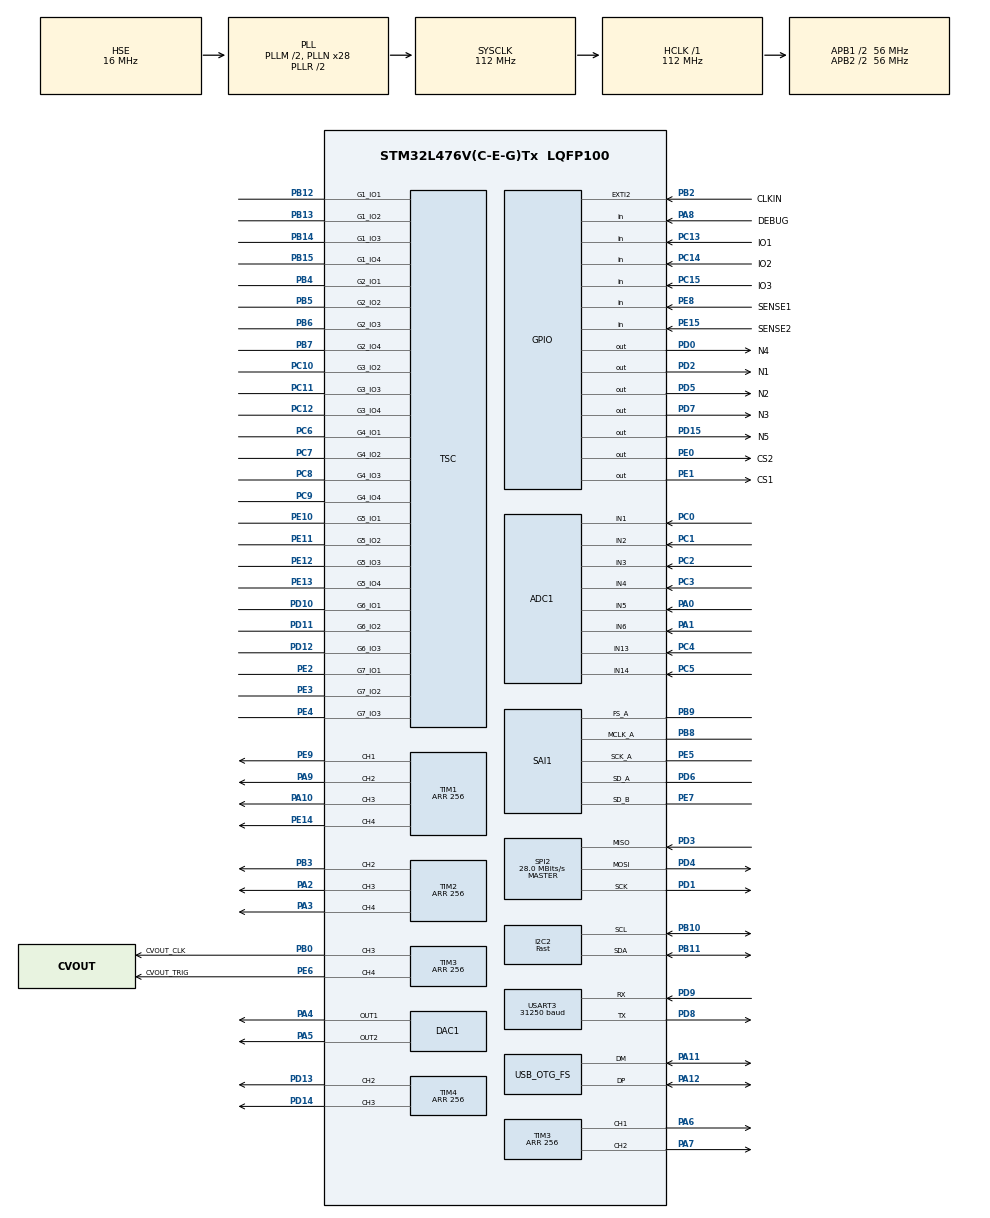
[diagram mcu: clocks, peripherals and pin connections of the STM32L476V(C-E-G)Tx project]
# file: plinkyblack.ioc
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Dma.USART3_RX.6.Instance=DMA1_Channel3
Dma.SPI2_TX.2.PeriphInc=DMA_PINC_DISABLE
Dma.SPI2_TX.2.MemInc=DMA_MINC_ENABLE
VP_TIM5_VS_ClockSourceINT.Mode=Internal
SH.S_TIM1_CH4.0=TIM1_CH4,PWM Generation4 CH4
TSC.ChannelIOs-G6_IO2=TSC_GROUP6_IO2
TSC.ChannelIOs-G6_IO3=TSC_GROUP6_IO3
Dma.SAI1_B.4.Priority=DMA_PRIORITY_LOW
SPI2.VirtualType=VM_MASTER
PB10.Mode=I2C
Dma.SAI1_B.4.MemInc=DMA_MINC_ENABLE
ADC1.SamplingTime-6\#ChannelRegularConversion=ADC_SAMPLETIME_24CYCLES_5
PC12.Signal=TSC_G3_IO4
PE8.GPIO_PuPd=GPIO_PULLUP
PE1.PinState=GPIO_PIN_SET
SAI1.Instance-SAI_A_MasterWithClock=SAI$Index_Block_A
PA15\ (JTDI).Signal=SYS_JTDI
RCC.DATA_CACHE_ENABLE=0
PB13.Signal=TSC_G1_IO2
TIM3.Channel-PWM\ Generation4\ CH4=TIM_CHANNEL_4
PE6.GPIO_Label=CVOUT_TRIG
RCC.SYSCLKSource=RCC_SYSCLKSOURCE_PLLCLK
NVIC.DMA1_Channel3_IRQn=true\:0\:0\:false\:false\:true\:false\:true
USART3.VirtualMode-Asynchronous=VM_ASYNC
PA14\ (JTCK-SWCLK).Signal=SYS_JTCK-SWCLK
USART3.BaudRate=31250
ADC1.Channel-5\#ChannelRegularConversion=ADC_CHANNEL_6
RCC.ADCCLockSelection=RCC_ADCCLKSOURCE_PLLSAI2
Dma.USART3_TX.5.PeriphDataAlignment=DMA_PDATAALIGN_BYTE
PE2.Mode=G7_IO1-Sampling
PD4.Signal=SPI2_MOSI
I2C2.I2C_Speed_Mode=I2C_Fast
RCC.APB2TimFreq_Value=112000000
PB6.Signal=TSC_G2_IO3
ADC1.Channel-2\#ChannelRegularConversion=ADC_CHANNEL_3
PC7.Signal=TSC_G4_IO2
Dma.ADC1.1.PeriphDataAlignment=DMA_PDATAALIGN_HALFWORD
TSC.SpreadSpectrum=DISABLE
PB6.Mode=G2_IO3-Channel
PC3.Signal=ADCx_IN4
PD0.Signal=GPIO_Output
PD8.Signal=USART3_TX
PE5.Signal=SAI1_SCK_A
PE1.Signal=GPIO_Output
RCC.PREFETCH_ENABLE=1
TIM4.Channel-PWM\ Generation3\ CH3=TIM_CHANNEL_3
TIM1.OCFastMode_PWM-PWM\ Generation4\ CH4=TIM_OCFAST_ENABLE
PB2.Signal=GPXTI2
Dma.USART3_RX.6.Direction=DMA_PERIPH_TO_MEMORY
Dma.SAI1_B.4.Instance=DMA2_Channel2
RCC.SAI1CLockSelection=RCC_SAI1CLKSOURCE_PLLSAI2
TIM1.Channel-PWM\ Generation1\ CH1=TIM_CHANNEL_1
PE9.Signal=S_TIM1_CH1
PB14.Mode=G1_IO3-Channel
PC9.Mode=G4_IO4-Channel
SPI2.CalculateBaudRate=28.0 MBits/s
TSC.ChannelIOs-G5_IO4=TSC_GROUP5_IO4
SH.S_TIM4_CH2.0=TIM4_CH2,PWM Generation2 CH2
TSC.ChannelIOs-G5_IO3=TSC_GROUP5_IO3
TSC.ChannelIOs-G5_IO2=TSC_GROUP5_IO2
PE2.Signal=TSC_G7_IO1
PA8.Signal=GPIO_Input
PE13.Mode=G5_IO4-Channel
TIM4.Period=256
PD3.Mode=Full_Duplex_Master
PE10.Signal=TSC_G5_IO1
PB2.GPIO_PuPd=GPIO_PULLUP
VP_TIM1_VS_ClockSourceINT.Mode=Internal
ADC1.SamplingTime-0\#ChannelRegularConversion=ADC_SAMPLETIME_24CYCLES_5
PA0.Signal=ADCx_IN5
ADC1.OffsetNumber-5\#ChannelRegularConversion=ADC_OFFSET_NONE
Mcu.Package=LQFP100
PB9.Signal=SAI1_FS_A
SAI1.AudioFrequency-SAI_A_MasterWithClock=SAI_AUDIO_FREQUENCY_32K
SPI2.Mode=SPI_MODE_MASTER
ADC1.OversamplingMode=ENABLE
SH.ADCx_IN14.0=ADC1_IN14,IN14-Single-Ended
PD12.Signal=TSC_G6_IO3
TIM1.OCFastMode_PWM-PWM\ Generation3\ CH3=TIM_OCFAST_ENABLE
Dma.SPI2_TX.2.Mode=DMA_NORMAL
PA10.Signal=S_TIM1_CH3
PC11.Mode=G3_IO3-Channel
TIM2.OCFastMode_PWM-PWM\ Generation4\ CH4=TIM_OCFAST_ENABLE
RCC.APB2CLKDivider=RCC_HCLK_DIV2
NVIC.EXTI2_IRQn=true\:0\:0\:false\:false\:true\:true\:true
PD4.Mode=Full_Duplex_Master
RCC.APB1TimFreq_Value=112000000
TIM1.Period=256
PB13.Mode=G1_IO2-Channel
NVIC.DMA1_Channel4_IRQn=true\:0\:0\:false\:false\:true\:false\:true
PA13\ (JTMS-SWDIO).Signal=SYS_JTMS-SWDIO
TSC.MaxCountValue=TSC_MCV_16383
PD9.GPIO_PuPd=GPIO_PULLUP
PH0-OSC_IN\ (PH0).Mode=HSE-External-Oscillator
ADC1.EOCSelection=ADC_EOC_SEQ_CONV
PD15.Signal=GPIO_Output
TSC.SamplingIOs-G1_IO1=TSC_GROUP1_IO1
ADC1.Rank-4\#ChannelRegularConversion=5
PE12.Mode=G5_IO3-Channel
USART3.RxPinLevelInvertParam=ADVFEATURE_RXINV_DISABLE
Dma.SAI1_B.4.PeriphInc=DMA_PINC_DISABLE
PC15-OSC32_OUT\ (PC15).GPIO_Label=IO3
ADC1.Rank-0\#ChannelRegularConversion=1
DAC1.DAC_Channel-DAC_OUT2=DAC_CHANNEL_2
VP_SAI1_VP_$IpInstance_SAIA_SAI_BASIC.Mode=SAI_A_BASIC
Dma.USART3_RX.6.MemDataAlignment=DMA_MDATAALIGN_BYTE
SH.ADCx_IN6.0=ADC1_IN6,IN6-Single-Ended
SAI1.MClockEnable-SAI_A_MasterWithClock=SAI_MASTERCLOCK_ENABLE
ADC1.OffsetNumber-0\#ChannelRegularConversion=ADC_OFFSET_NONE
PC13.Signal=GPIO_Input
PD3.Signal=SPI2_MISO
PC6.Signal=TSC_G4_IO1
PE10.Mode=G5_IO1-Sampling
PC2.Signal=ADCx_IN3
PD7.Signal=GPIO_Output
PD1.Signal=SPI2_SCK
Dma.USART3_TX.5.Instance=DMA1_Channel2
SAI1.ErrorAudioFreq-SAI_A_MasterWithClock=-2.34 %
Dma.SAI1_B.4.MemDataAlignment=DMA_MDATAALIGN_HALFWORD
PC0.Signal=ADCx_IN1
RCC.APB1CLKDivider=RCC_HCLK_DIV2
Dma.USART3_RX.6.PeriphInc=DMA_PINC_DISABLE
TSC.SamplingIOs-G6_IO1=TSC_GROUP6_IO1
PD6.Mode=SAI_A_MasterWithClock
PD0.GPIO_Speed=GPIO_SPEED_FREQ_LOW
ADC1.Channel-7\#ChannelRegularConversion=ADC_CHANNEL_14
PC14-OSC32_IN\ (PC14).GPIO_Label=IO2
PE0.GPIO_Speed=GPIO_SPEED_FREQ_VERY_HIGH
PD10.Signal=TSC_G6_IO1
TIM1.AutoReloadPreload=TIM_AUTORELOAD_PRELOAD_DISABLE
TIM3.Channel-PWM\ Generation3\ CH3=TIM_CHANNEL_3
PA8.GPIO_Label=DEBUG
PB11.Mode=I2C
SH.COMP_DAC11_group.0=DAC1_OUT1,DAC_OUT1
PC6.Mode=G4_IO1-Sampling
PE8.GPIO_Label=SENSE1
PA9.Signal=S_TIM1_CH2
TIM1.Channel-PWM\ Generation2\ CH2=TIM_CHANNEL_2
Dma.USART3_TX.5.PeriphInc=DMA_PINC_DISABLE
Dma.USART3_TX.5.Mode=DMA_NORMAL
PD8.Mode=Asynchronous
TSC.ChannelIOs-G7_IO3=TSC_GROUP7_IO3
TSC.ChannelIOs-G7_IO2=TSC_GROUP7_IO2
PB10.Signal=I2C2_SCL
SAI1.VirtualMode-SAI_A_MasterWithClock=VM_MASTER
TSC.CTPulseHighLength=TSC_CTPH_7CYCLES
VP_SAI1_VP_$IpInstance_SAIB_SAI_BASIC.Mode=SAI_B_BASIC
PB14.Signal=TSC_G1_IO3
PA5.Signal=COMP_DAC12_group
PC12.Mode=G3_IO4-Channel
PE1.GPIO_Label=CS1
PD1.Mode=Full_Duplex_Master
Dma.SAI1_A.0.PeriphInc=DMA_PINC_DISABLE
TSC.SamplingIOs-G7_IO1=TSC_GROUP7_IO1
PE14.Signal=S_TIM1_CH4
PE15.Signal=GPIO_Input
PE8.Signal=GPIO_Input
SH.ADCx_IN4.0=ADC1_IN4,IN4-Single-Ended
SAI1.FIFOThreshold-SAI_A_MasterWithClock=SAI_FIFOTHRESHOLD_HF
ADC1.DMAContinuousRequests=ENABLE
Dma.USART3_RX.6.Mode=DMA_CIRCULAR
TIM2.Period=256
PB4\ (NJTRST).Mode=G2_IO1-Sampling
Dma.SAI1_B.4.PeriphDataAlignment=DMA_PDATAALIGN_HALFWORD
ADC1.ExternalTrigConv=ADC_EXTERNALTRIG_T6_TRGO
PC8.Mode=G4_IO3-Channel
PA13\ (JTMS-SWDIO).Mode=Serial_Wire
PA4.Signal=COMP_DAC11_group
ADC1.SamplingTime-1\#ChannelRegularConversion=ADC_SAMPLETIME_24CYCLES_5
PB5.Signal=TSC_G2_IO2
ADC1.master=1
PD12.Mode=G6_IO3-Channel
PD11.Signal=TSC_G6_IO2
ADC1.Rank-1\#ChannelRegularConversion=2
PA11.Signal=USB_OTG_FS_DM
NVIC.DMA2_Channel1_IRQn=true\:1\:0\:true\:false\:true\:false\:true
ProjectManager.HeapSize=0x200
ADC1.SamplingTime-5\#ChannelRegularConversion=ADC_SAMPLETIME_24CYCLES_5
SH.ADCx_IN5.0=ADC1_IN5,IN5-Single-Ended
VP_TIM4_VS_ClockSourceINT.Mode=Internal
SAI1.VirtualProtocol-SAI_B_BASIC=VM_BASIC_PROTOCOL
NVIC.PriorityGroup=NVIC_PRIORITYGROUP_4
TIM3.Channel-PWM\ Generation2\ CH2=TIM_CHANNEL_2
PB8.Mode=SAI_A_MasterWithClock
TSC.CTPulseLowLength=TSC_CTPL_7CYCLES
PE3.Signal=TSC_G7_IO2
TIM2.AutoReloadPreload=TIM_AUTORELOAD_PRELOAD_DISABLE
SPI2.DataSize=SPI_DATASIZE_8BIT
NVIC.DMA1_Channel1_IRQn=true\:0\:0\:false\:false\:true\:false\:true
TIM1.Channel-PWM\ Generation3\ CH3=TIM_CHANNEL_3
PD2.Signal=GPIO_Output
PB0.Signal=S_TIM3_CH3
ADC1.Rank-5\#ChannelRegularConversion=6
RCC.USART3CLockSelection=RCC_USART3CLKSOURCE_HSI
PC1.Signal=ADCx_IN2
Dma.SAI1_A.0.Instance=DMA2_Channel1
Dma.USART3_RX.6.PeriphDataAlignment=DMA_PDATAALIGN_BYTE
PD2.GPIO_Label=N1
Dma.SAI1_A.0.PeriphDataAlignment=DMA_PDATAALIGN_HALFWORD
Mcu.Family=STM32L4
NVIC.USART3_IRQn=true\:0\:0\:false\:false\:true\:true\:true
Dma.USART3_TX.5.MemInc=DMA_MINC_ENABLE
RCC.CortexFreq_Value=112000000
Dma.ADC1.1.MemDataAlignment=DMA_MDATAALIGN_HALFWORD
NVIC.DMA1_Channel5_IRQn=true\:0\:0\:false\:false\:true\:false\:true
PC14-OSC32_IN\ (PC14).GPIO_PuPd=GPIO_PULLUP
ADC1.OffsetNumber-7\#ChannelRegularConversion=ADC_OFFSET_NONE
ADC1.ContinuousConvMode=DISABLE
PH0-OSC_IN\ (PH0).Signal=RCC_OSC_IN
SH.COMP_DAC12_group.0=DAC1_OUT2,DAC_OUT2
SH.ADCx_IN2.0=ADC1_IN2,IN2-Single-Ended
PC10.Signal=TSC_G3_IO2
ADC1.OffsetNumber-4\#ChannelRegularConversion=ADC_OFFSET_NONE
I2C2.Timing=0x00501D63
SAI1.VirtualProtocol-SAI_A_BASIC=VM_BASIC_PROTOCOL
PD0.GPIO_Label=N4
PA11.Mode=Device_Only
PB0.GPIO_Label=CVOUT_CLK
TSC.ChannelIOs-G2_IO2=TSC_GROUP2_IO2
TIM1.OCFastMode_PWM-PWM\ Generation1\ CH1=TIM_OCFAST_ENABLE
TSC.ChannelIOs-G2_IO3=TSC_GROUP2_IO3
TIM2.Channel-PWM\ Generation2\ CH2=TIM_CHANNEL_2
TSC.ChannelIOs-G2_IO4=TSC_GROUP2_IO4
PC13.GPIO_Label=IO1
PB11.Signal=I2C2_SDA
PB15.Signal=TSC_G1_IO4
PD9.Mode=Asynchronous
ProjectManager.StackSize=0x400
PB3\ (JTDO-TRACESWO).Signal=S_TIM2_CH2
PD13.Signal=S_TIM4_CH2
PB2.GPIO_ModeDefaultEXTI=GPIO_MODE_IT_FALLING
PA12.Signal=USB_OTG_FS_DP
Dma.SAI1_B.4.Mode=DMA_CIRCULAR
SPI2.CLKPolarity=SPI_POLARITY_HIGH
PE11.Mode=G5_IO2-Channel
SAI1.VirtualMode-SAI_B_SyncSlave=VM_SLAVE
TSC.SamplingIOs-G4_IO1=TSC_GROUP4_IO1
Dma.ADC1.1.Instance=DMA1_Channel1
TIM1.Channel-PWM\ Generation4\ CH4=TIM_CHANNEL_4
ADC1.Channel-3\#ChannelRegularConversion=ADC_CHANNEL_4
RCC.HCLKFreq_Value=112000000
SH.ADCx_IN3.0=ADC1_IN3,IN3-Single-Ended
TIM3.Period=256
Dma.SPI2_TX.2.PeriphDataAlignment=DMA_PDATAALIGN_BYTE
PD10.Mode=G6_IO1-Sampling
Dma.SPI2_TX.2.Instance=DMA1_Channel5
Dma.SPI2_RX.3.Priority=DMA_PRIORITY_HIGH
RCC.AHBFreq_Value=112000000
SPI2.BaudRatePrescaler=SPI_BAUDRATEPRESCALER_2
TIM3.Channel-PWM\ Generation1\ CH1=TIM_CHANNEL_1
Dma.USART3_TX.5.Direction=DMA_MEMORY_TO_PERIPH
ADC1.Channel-0\#ChannelRegularConversion=ADC_CHANNEL_1
PH1-OSC_OUT\ (PH1).Mode=HSE-External-Oscillator
NVIC.DMA2_Channel2_IRQn=true\:1\:0\:true\:false\:true\:false\:true
RCC.HSE_VALUE=16000000
ADC1.SamplingTime-4\#ChannelRegularConversion=ADC_SAMPLETIME_24CYCLES_5
ADC1.Channel-6\#ChannelRegularConversion=ADC_CHANNEL_13
ADC1.Rank-2\#ChannelRegularConversion=3
PE13.Signal=TSC_G5_IO4
PD0.PinState=GPIO_PIN_RESET
Dma.SPI2_RX.3.PeriphDataAlignment=DMA_PDATAALIGN_BYTE
PB5.Mode=G2_IO2-Channel
Dma.ADC1.1.Priority=DMA_PRIORITY_LOW
PC13.GPIO_PuPd=GPIO_PULLUP
SAI1.InitProtocol-SAI_A_MasterWithClock=Enable
RCC.PLLSAI2N=14
PB7.Signal=TSC_G2_IO4
Dma.ADC1.1.Mode=DMA_CIRCULAR
TSC.PulseGeneratorPrescaler=TSC_PG_PRESC_DIV2
TSC.SamplingIOs-G5_IO1=TSC_GROUP5_IO1
PE4.Mode=G7_IO3-Channel
SH.S_TIM3_CH1.0=TIM3_CH1,PWM Generation1 CH1
TIM6.Period=12000
TIM4.OCFastMode_PWM-PWM\ Generation2\ CH2=TIM_OCFAST_ENABLE
Dma.SPI2_TX.2.MemDataAlignment=DMA_MDATAALIGN_BYTE
PE4.Signal=TSC_G7_IO3
TSC.SpreadSpectrumPrescaler=TSC_SS_PRESC_DIV1
PD7.GPIO_Label=N3
SAI1.OutputDrive-SAI_A_MasterWithClock=SAI_OUTPUTDRIVE_ENABLE
PA6.Signal=S_TIM3_CH1
PB12.Mode=G1_IO1-Sampling
TSC.ChannelIOs-G1_IO4=TSC_GROUP1_IO4
Dma.SPI2_TX.2.Priority=DMA_PRIORITY_HIGH
TSC.ChannelIOs-G1_IO2=TSC_GROUP1_IO2
TSC.ChannelIOs-G1_IO3=TSC_GROUP1_IO3
Dma.USART3_TX.5.Priority=DMA_PRIORITY_LOW
Dma.SAI1_A.0.MemDataAlignment=DMA_MDATAALIGN_HALFWORD
Dma.ADC1.1.Direction=DMA_PERIPH_TO_MEMORY
RCC.EnbaleCSS=true
PD5.GPIO_Label=N2
Dma.ADC1.1.MemInc=DMA_MINC_ENABLE
USB_OTG_FS.VirtualMode=Device_Only
ADC1.OffsetNumber-1\#ChannelRegularConversion=ADC_OFFSET_NONE
SPI2.CLKPhase=SPI_PHASE_2EDGE
PE0.GPIO_Label=CS2
Dma.SPI2_RX.3.Mode=DMA_NORMAL
SH.ADCx_IN1.0=ADC1_IN1,IN1-Single-Ended
Dma.Request2=SPI2_TX
Dma.Request1=ADC1
Dma.Request4=SAI1_B
Dma.Request3=SPI2_RX
USART3.OverrunDisableParam=ADVFEATURE_OVERRUN_DISABLE
Dma.Request6=USART3_RX
Dma.SPI2_RX.3.PeriphInc=DMA_PINC_DISABLE
Dma.Request5=USART3_TX
SPI2.Direction=SPI_DIRECTION_2LINES
PC5.Signal=ADCx_IN14
PE7.Signal=SAI1_SD_B
PD6.Signal=SAI1_SD_A
ADC1.Rank-6\#ChannelRegularConversion=7
Dma.Request0=SAI1_A
PE3.Mode=G7_IO2-Channel
Dma.SAI1_B.4.Direction=DMA_PERIPH_TO_MEMORY
VP_TIM3_VS_ClockSourceINT.Mode=Internal
RCC.PLLSAI1N=12
PA3.Signal=S_TIM2_CH4
RCC.MSI_VALUE=4000000
RCC.PLLSourceVirtual=RCC_PLLSOURCE_HSE
PA14\ (JTCK-SWCLK).Mode=Serial_Wire
TIM2.Channel-PWM\ Generation4\ CH4=TIM_CHANNEL_4
SH.ADCx_IN13.0=ADC1_IN13,IN13-Single-Ended
TIM4.AutoReloadPreload=TIM_AUTORELOAD_PRELOAD_DISABLE
PD15.GPIO_Label=N5
ADC1.Channel-4\#ChannelRegularConversion=ADC_CHANNEL_5
Dma.SAI1_A.0.Direction=DMA_MEMORY_TO_PERIPH
PC11.Signal=TSC_G3_IO3
ADC1.OffsetNumber-3\#ChannelRegularConversion=ADC_OFFSET_NONE
PC8.Signal=TSC_G4_IO3
PC4.Signal=ADCx_IN13
PC10.Mode=G3_IO2-Sampling
VP_TIM6_VS_ClockSourceINT.Mode=Enable_Timer
TSC.ChannelIOs-G4_IO4=TSC_GROUP4_IO4
Dma.SPI2_RX.3.MemDataAlignment=DMA_MDATAALIGN_BYTE
TSC.ChannelIOs-G4_IO3=TSC_GROUP4_IO3
PC15-OSC32_OUT\ (PC15).Signal=GPIO_Input
PD9.Signal=USART3_RX
PD5.Signal=GPIO_Output
TSC.ChannelIOs-G4_IO2=TSC_GROUP4_IO2
Dma.SAI1_A.0.MemInc=DMA_MINC_ENABLE
TIM4.OCFastMode_PWM-PWM\ Generation3\ CH3=TIM_OCFAST_ENABLE
SH.S_TIM3_CH3.0=TIM3_CH3,PWM Generation3 CH3
ADC1.SamplingTime-2\#ChannelRegularConversion=ADC_SAMPLETIME_24CYCLES_5
PH1-OSC_OUT\ (PH1).Signal=RCC_OSC_OUT
TIM1.OCFastMode_PWM-PWM\ Generation2\ CH2=TIM_OCFAST_ENABLE
Dma.USART3_RX.6.MemInc=DMA_MINC_ENABLE
Dma.SPI2_RX.3.MemInc=DMA_MINC_ENABLE
TSC.SamplingIOs-G2_IO1=TSC_GROUP2_IO1
SAI1.RealAudioFreq-SAI_A_MasterWithClock=31.25 KHz
SH.S_TIM2_CH2.0=TIM2_CH2,PWM Generation2 CH2
PE0.PinState=GPIO_PIN_SET
SH.S_TIM1_CH1.0=TIM1_CH1,PWM Generation1 CH1
PE15.GPIO_Label=SENSE2
NVIC.DMA1_Channel2_IRQn=true\:0\:0\:false\:false\:true\:false\:true
ProjectManager.TargetToolchain=STM32CubeIDE
Dma.SAI1_A.0.Mode=DMA_CIRCULAR
Dma.SPI2_TX.2.Direction=DMA_MEMORY_TO_PERIPH
SH.S_TIM4_CH3.0=TIM4_CH3,PWM Generation3 CH3
PB9.Mode=SAI_A_MasterWithClock
ADC1.Channel-1\#ChannelRegularConversion=ADC_CHANNEL_2
TSC.SpreadSpectrumDeviation=32
RCC.USBFreq_Value=48000000
TIM2.OCFastMode_PWM-PWM\ Generation3\ CH3=TIM_OCFAST_ENABLE
ADC1.Ratio=ADC_OVERSAMPLING_RATIO_16
PE11.Signal=TSC_G5_IO2
RCC.LSE_VALUE=32768
PA1.Signal=ADCx_IN6
Dma.SAI1_A.0.Priority=DMA_PRIORITY_LOW
SH.S_TIM3_CH2.0=TIM3_CH2,PWM Generation2 CH2
board=custom
RCC.VCOOutputFreq_Value=224000000
Dma.SPI2_RX.3.Instance=DMA1_Channel4
PB15.Mode=G1_IO4-Channel
PC15-OSC32_OUT\ (PC15).GPIO_PuPd=GPIO_PULLUP
TIM4.Channel-PWM\ Generation2\ CH2=TIM_CHANNEL_2
RCC.APB2Freq_Value=56000000
SH.S_TIM1_CH2.0=TIM1_CH2,PWM Generation2 CH2
VP_TIM2_VS_ClockSourceINT.Mode=Internal
SH.S_TIM2_CH3.0=TIM2_CH3,PWM Generation3 CH3
PE1.GPIO_Speed=GPIO_SPEED_FREQ_VERY_HIGH
RCC.INSTRUCTION_CACHE_ENABLE=1
PE5.Mode=SAI_A_MasterWithClock
RCC.ADCFreq_Value=56000000
TIM2.Channel-PWM\ Generation3\ CH3=TIM_CHANNEL_3
TIM6.TIM_MasterOutputTrigger=TIM_TRGO_UPDATE
Dma.USART3_RX.6.Priority=DMA_PRIORITY_LOW
Dma.ADC1.1.PeriphInc=DMA_PINC_DISABLE
DAC1.DAC_Trigger-DAC_OUT2=DAC_TRIGGER_NONE
DAC1.DAC_Trigger-DAC_OUT1=DAC_TRIGGER_NONE
PE6.Signal=S_TIM3_CH4
ADC1.NbrOfConversion=8
ADC1.OffsetNumber-2\#ChannelRegularConversion=ADC_OFFSET_NONE
Mcu.Name=STM32L476V(C-E-G)Tx
PE0.Signal=GPIO_Output
PE12.Signal=TSC_G5_IO3
PA2.Signal=S_TIM2_CH3
ADC1.OffsetNumber-6\#ChannelRegularConversion=ADC_OFFSET_NONE
PD14.Signal=S_TIM4_CH3
RCC.SYSCLKFreq_VALUE=112000000
TSC.ChannelIOs-G3_IO4=TSC_GROUP3_IO4
PE7.Mode=SAI_B_SyncSlave
TSC.ChannelIOs-G3_IO3=TSC_GROUP3_IO3
PA12.Mode=Device_Only
ADC1.Rank-3\#ChannelRegularConversion=4
ADC1.SamplingTime-3\#ChannelRegularConversion=ADC_SAMPLETIME_24CYCLES_5
TIM5.Prescaler=80
TSC.SamplingIOs-G3_IO2=TSC_GROUP3_IO2
PC14-OSC32_IN\ (PC14).Signal=GPIO_Input
SAI1.Instance-SAI_B_SyncSlave=SAI$Index_Block_B
PB7.Mode=G2_IO4-Channel
PB2.GPIO_Label=CLKIN
PE15.GPIO_PuPd=GPIO_PULLUP
SH.S_TIM2_CH4.0=TIM2_CH4,PWM Generation4 CH4
Dma.USART3_TX.5.MemDataAlignment=DMA_MDATAALIGN_BYTE
PD11.Mode=G6_IO2-Channel
SH.S_TIM1_CH3.0=TIM1_CH3,PWM Generation3 CH3
NVIC.I2C2_EV_IRQn=true\:0\:0\:false\:false\:true\:true\:true
RCC.HSI_VALUE=16000000
PA8.GPIO_PuPd=GPIO_PULLUP
ADC1.Rank-7\#ChannelRegularConversion=8
ADC1.NbrOfConversionFlag=1
RCC.PLLM=2
RCC.PLLN=28
PB8.Signal=SAI1_MCLK_A
TIM5.Period=4294967295
PC9.Signal=TSC_G4_IO4
ADC1.SamplingTime-7\#ChannelRegularConversion=ADC_SAMPLETIME_24CYCLES_5
PC7.Mode=G4_IO2-Channel
RCC.APB1Freq_Value=56000000
SAI1.InitProtocol-SAI_B_SyncSlave=Enable
ADC1.ClockPrescaler=ADC_CLOCK_ASYNC_DIV2
Dma.SPI2_RX.3.Direction=DMA_PERIPH_TO_MEMORY
PB12.Signal=TSC_G1_IO1
SH.S_TIM3_CH4.0=TIM3_CH4,PWM Generation4 CH4
PA7.Signal=S_TIM3_CH2
PB4\ (NJTRST).Signal=TSC_G2_IO1

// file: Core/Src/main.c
/* USER CODE BEGIN Header */
/**
 ******************************************************************************
 * @file           : main.c
 * @brief          : Main program body
 ******************************************************************************
 * @attention
 *
 * <h2><center>&copy; Copyright (c) 2020 STMicroelectronics.
 * All rights reserved.</center></h2>
 *
 * This software component is licensed by ST under BSD 3-Clause license,
 * the "License"; You may not use this file except in compliance with the
 * License. You may obtain a copy of the License at:
 *                        opensource.org/licenses/BSD-3-Clause
 *
 ******************************************************************************
 */
/* USER CODE END Header */

#include "main.h"

/* USER CODE BEGIN Includes */
#define FLASH_LATENCY_5 FLASH_LATENCY_4 // WOOHAHAHAHAH
#include "core.h"
#include <stdlib.h>
#include <string.h>
/* USER CODE END Includes */

ADC_HandleTypeDef hadc1;
DMA_HandleTypeDef hdma_adc1;

DAC_HandleTypeDef hdac1;

I2C_HandleTypeDef hi2c2;

SAI_HandleTypeDef hsai_BlockA1;
SAI_HandleTypeDef hsai_BlockB1;
DMA_HandleTypeDef hdma_sai1_a;
DMA_HandleTypeDef hdma_sai1_b;

SPI_HandleTypeDef hspi2;
DMA_HandleTypeDef hdma_spi2_tx;
DMA_HandleTypeDef hdma_spi2_rx;

TIM_HandleTypeDef htim1;
TIM_HandleTypeDef htim2;
TIM_HandleTypeDef htim3;
TIM_HandleTypeDef htim4;
TIM_HandleTypeDef htim5;
TIM_HandleTypeDef htim6;

TSC_HandleTypeDef htsc;

UART_HandleTypeDef huart3;
DMA_HandleTypeDef hdma_usart3_tx;
DMA_HandleTypeDef hdma_usart3_rx;

PCD_HandleTypeDef hpcd_USB_OTG_FS;

/* USER CODE BEGIN PV */
// https://github.com/STMicroelectronics/STMems_Standard_C_drivers/blob/master/lis2dh12_STdC/example/lis2dh12_read_data_polling.c
#include "lis2dh12_reg.h"
#define SENSOR_BUS hi2c2

static int32_t platform_write(void *handle, uint8_t reg,
                              uint8_t *bufp,
                              uint16_t len)
{
  /* Write multiple command */
  reg |= 0x80;
  HAL_I2C_Mem_Write(handle, LIS2DH12_I2C_ADD_L, reg,
                    I2C_MEMADD_SIZE_8BIT, bufp, len, I2C_TIMEOUT);
  return 0;
}

static int32_t platform_read(void *handle, uint8_t reg, uint8_t *bufp,
                             uint16_t len)
{
  /* Read multiple command */
  reg |= 0x80;
  HAL_I2C_Mem_Read(handle, LIS2DH12_I2C_ADD_L, reg,
                   I2C_MEMADD_SIZE_8BIT, bufp, len, I2C_TIMEOUT);
  return 0;
}

stmdev_ctx_t accelerometer = {
		  .write_reg = platform_write,
		  .read_reg = platform_read,
		  .handle = &SENSOR_BUS
};

/* USER CODE END PV */

void SystemClock_Config(void);
static void MX_GPIO_Init(void);
static void MX_DMA_Init(void);
static void MX_USART3_UART_Init(void);
static void MX_TIM1_Init(void);
static void MX_TIM2_Init(void);
static void MX_TIM4_Init(void);
static void MX_TSC_Init(void);
static void MX_I2C2_Init(void);
static void MX_ADC1_Init(void);
static void MX_DAC1_Init(void);
static void MX_SAI1_Init(void);
static void MX_SPI2_Init(void);
static void MX_TIM3_Init(void);
static void MX_TIM6_Init(void);
static void MX_TIM5_Init(void);
static void MX_USB_OTG_FS_PCD_Init(void);

/* USER CODE BEGIN 0 */
extern volatile u8 gotclkin;

//void HAL_GPIO_EXTI_Callback(uint16_t GPIO_Pin) {
//	gotclkin++;
//}
u8 lastencstate=0;
extern volatile int encval;
extern volatile u8 encbtn;
const static s8 encdeltas[16]={
		 0, 1,-1, 0,
		-1, 0, 0, 1,
		 1, 0, 0,-1,
		 0,-1, 1, 0
};
static inline u8 ReadEncState(void) {
	return (GPIOC->IDR >> 14)&3;
}
extern float encaccel;
void EncoderTick(void) {
    encbtn = !((GPIOC->IDR >> 13) & 1) ;
	u8 newstate=ReadEncState();
	int st=lastencstate + (newstate<<2);
    int oldencval = encval;
	if (newstate==3) //if (st==15)
		encval=((encval>>2)<<2)+2; // snap to the middle of a sector when the switch is idle for 2ms
	else
		encval-=encdeltas[st];
    encaccel *= 0.998f;
    encaccel += abs(oldencval - encval) * 0.125f;
	lastencstate=newstate;
}

extern volatile bool clkin_is_euro;

void ClockIRQ(void){
	gotclkin++;
  clkin_is_euro = true;
}

int16_t accel_raw[3];
float accel_lpf[2];
float accel_smooth[2];
bool update_accelerometer_raw(void) {
	if (!accelerometer.handle) return false;
	    lis2dh12_reg_t reg;
	    lis2dh12_xl_data_ready_get(&accelerometer, &reg.byte);
	    if (!reg.byte)
	    	return false;
	  /* Read accelerometer data */
	  int16_t tmp[3]={0,0,0 };
	  lis2dh12_acceleration_raw_get(&accelerometer, tmp);
	  accel_raw[0]=tmp[0];
	  accel_raw[1]=tmp[1];
	  accel_raw[2]=tmp[2];
	  return true;
}

int miditest(void);
void midiinit(void);

/* USER CODE END 0 */

int main(void)
{

  /* MCU Configuration--------------------------------------------------------*/

  /* Reset of all peripherals, Initializes the Flash interface and the Systick. */
  HAL_Init();

  /* Configure the system clock */
  SystemClock_Config();

  /* Initialize all configured peripherals */
  MX_GPIO_Init();
  MX_DMA_Init();
  MX_USART3_UART_Init();
  MX_TIM1_Init();
  MX_TIM2_Init();
  MX_TIM4_Init();
  MX_TSC_Init();
  MX_I2C2_Init();
  MX_ADC1_Init();
  MX_DAC1_Init();
  MX_SAI1_Init();
  MX_SPI2_Init();
  MX_TIM3_Init();
  MX_TIM6_Init();
  MX_TIM5_Init();
  MX_USB_OTG_FS_PCD_Init();
  /* USER CODE BEGIN 2 */
  // check if the bootloader wants us to flash

  HAL_Delay(8);
  uint8_t whoamI=0;
  lis2dh12_device_id_get(&accelerometer, &whoamI);
  if (whoamI != LIS2DH12_ID) {
      accelerometer.handle=0;
    } else {
	  lis2dh12_block_data_update_set(&accelerometer, PROPERTY_ENABLE);
	  lis2dh12_data_rate_set(&accelerometer, LIS2DH12_ODR_100Hz);
	  lis2dh12_full_scale_set(&accelerometer, LIS2DH12_2g);
	  lis2dh12_temperature_meas_set(&accelerometer, LIS2DH12_TEMP_DISABLE);
	  lis2dh12_operating_mode_set(&accelerometer, LIS2DH12_HR_12bit);
/* accel debug
	  while (1) {
		  update_accelerometer_raw();
		  DebugLog("accel %5d %5d %5d\r\n",accel_raw[0], accel_raw[1], accel_raw[2]);
		  HAL_Delay(100);
	  }
	  */
    }

  //check_bootloader_flash(); // used to be here, but now we do it in plinky_init

  //  miditest();

#ifdef NEW_PINOUT
// for the new pinout, we use the stm's internal voltage reference
  HAL_SYSCFG_VREFBUF_VoltageScalingConfig(SYSCFG_VREFBUF_VOLTAGE_SCALE1);
  HAL_SYSCFG_EnableVREFBUF();
  HAL_SYSCFG_VREFBUF_HighImpedanceConfig(SYSCFG_VREFBUF_HIGH_IMPEDANCE_DISABLE);
  #else
// for the old pinout, pd0 is the cs line, needs to be fast!
  GPIO_InitTypeDef GPIO_InitStruct = { 0 };
  GPIO_InitStruct.Pin = GPIO_PIN_0;
  GPIO_InitStruct.Mode = GPIO_MODE_OUTPUT_PP;
  GPIO_InitStruct.Pull = GPIO_NOPULL;
  GPIO_InitStruct.Speed = GPIO_SPEED_FREQ_VERY_HIGH;
  HAL_GPIO_Init(GPIOD, &GPIO_InitStruct);
  // pd14 is not a timer, its gpiout for N4. hopefully this undoes the timer config of tim4 ch3 in TIM4_Init
  GPIO_InitStruct.Pin = GPIO_PIN_14;
  GPIO_InitStruct.Mode = GPIO_MODE_OUTPUT_PP;
  GPIO_InitStruct.Pull = GPIO_NOPULL;
  GPIO_InitStruct.Speed = GPIO_SPEED_LOW;
  HAL_GPIO_Init(GPIOD, &GPIO_InitStruct);
#endif

//	DebugLog("plinky black 0.1\r\n");
  void plinky_init(void);
  plinky_init();
  gotclkin=0;
  lastencstate=ReadEncState();
  encval=2;
  /* USER CODE END 2 */

  /* Infinite loop */
  /* USER CODE BEGIN WHILE */

  midiinit();

	while (1) {
    /* USER CODE END WHILE */

    /* USER CODE BEGIN 3 */
		void plinky_frame(void);
		plinky_frame();

	}
  /* USER CODE END 3 */
}

void SystemClock_Config(void)
{
  RCC_OscInitTypeDef RCC_OscInitStruct = {0};
  RCC_ClkInitTypeDef RCC_ClkInitStruct = {0};
  RCC_PeriphCLKInitTypeDef PeriphClkInit = {0};

  /** Initializes the CPU, AHB and APB busses clocks
  */
  RCC_OscInitStruct.OscillatorType = RCC_OSCILLATORTYPE_HSI|RCC_OSCILLATORTYPE_HSE;
  RCC_OscInitStruct.HSEState = RCC_HSE_ON;
  RCC_OscInitStruct.HSIState = RCC_HSI_ON;
  RCC_OscInitStruct.HSICalibrationValue = RCC_HSICALIBRATION_DEFAULT;
  RCC_OscInitStruct.PLL.PLLState = RCC_PLL_ON;
  RCC_OscInitStruct.PLL.PLLSource = RCC_PLLSOURCE_HSE;
  RCC_OscInitStruct.PLL.PLLM = 2;
  RCC_OscInitStruct.PLL.PLLN = 28;
  RCC_OscInitStruct.PLL.PLLP = RCC_PLLP_DIV7;
  RCC_OscInitStruct.PLL.PLLQ = RCC_PLLQ_DIV2;
  RCC_OscInitStruct.PLL.PLLR = RCC_PLLR_DIV2;
  if (HAL_RCC_OscConfig(&RCC_OscInitStruct) != HAL_OK)
  {
    Error_Handler();
  }
  /** Initializes the CPU, AHB and APB busses clocks
  */
  RCC_ClkInitStruct.ClockType = RCC_CLOCKTYPE_HCLK|RCC_CLOCKTYPE_SYSCLK
                              |RCC_CLOCKTYPE_PCLK1|RCC_CLOCKTYPE_PCLK2;
  RCC_ClkInitStruct.SYSCLKSource = RCC_SYSCLKSOURCE_PLLCLK;
  RCC_ClkInitStruct.AHBCLKDivider = RCC_SYSCLK_DIV1;
  RCC_ClkInitStruct.APB1CLKDivider = RCC_HCLK_DIV2;
  RCC_ClkInitStruct.APB2CLKDivider = RCC_HCLK_DIV2;

  if (HAL_RCC_ClockConfig(&RCC_ClkInitStruct, FLASH_LATENCY_5) != HAL_OK)
  {
    Error_Handler();
  }
  PeriphClkInit.PeriphClockSelection = RCC_PERIPHCLK_USART3|RCC_PERIPHCLK_SAI1
                              |RCC_PERIPHCLK_I2C2|RCC_PERIPHCLK_USB
                              |RCC_PERIPHCLK_ADC;
  PeriphClkInit.Usart3ClockSelection = RCC_USART3CLKSOURCE_HSI;
  PeriphClkInit.I2c2ClockSelection = RCC_I2C2CLKSOURCE_PCLK1;
  PeriphClkInit.Sai1ClockSelection = RCC_SAI1CLKSOURCE_PLLSAI2;
  PeriphClkInit.AdcClockSelection = RCC_ADCCLKSOURCE_PLLSAI2;
  PeriphClkInit.UsbClockSelection = RCC_USBCLKSOURCE_PLLSAI1;
  PeriphClkInit.PLLSAI2.PLLSAI2Source = RCC_PLLSOURCE_HSE;
  PeriphClkInit.PLLSAI2.PLLSAI2M = 2;
  PeriphClkInit.PLLSAI2.PLLSAI2N = 14;
  PeriphClkInit.PLLSAI2.PLLSAI2P = RCC_PLLP_DIV7;
  PeriphClkInit.PLLSAI2.PLLSAI2R = RCC_PLLR_DIV2;
  PeriphClkInit.PLLSAI2.PLLSAI2ClockOut = RCC_PLLSAI2_SAI2CLK|RCC_PLLSAI2_ADC2CLK;
  PeriphClkInit.PLLSAI1.PLLSAI1Source = RCC_PLLSOURCE_HSE;
  PeriphClkInit.PLLSAI1.PLLSAI1M = 2;
  PeriphClkInit.PLLSAI1.PLLSAI1N = 12;
  PeriphClkInit.PLLSAI1.PLLSAI1P = RCC_PLLP_DIV7;
  PeriphClkInit.PLLSAI1.PLLSAI1Q = RCC_PLLQ_DIV2;
  PeriphClkInit.PLLSAI1.PLLSAI1R = RCC_PLLR_DIV2;
  PeriphClkInit.PLLSAI1.PLLSAI1ClockOut = RCC_PLLSAI1_48M2CLK;
  if (HAL_RCCEx_PeriphCLKConfig(&PeriphClkInit) != HAL_OK)
  {
    Error_Handler();
  }
  /** Enables the Clock Security System
  */
  HAL_RCC_EnableCSS();
  /** Configure the main internal regulator output voltage
  */
  if (HAL_PWREx_ControlVoltageScaling(PWR_REGULATOR_VOLTAGE_SCALE1) != HAL_OK)
  {
    Error_Handler();
  }
}

static void MX_ADC1_Init(void)
{

  ADC_MultiModeTypeDef multimode = {0};
  ADC_ChannelConfTypeDef sConfig = {0};

  /** Common config
  */
  hadc1.Instance = ADC1;
  hadc1.Init.ClockPrescaler = ADC_CLOCK_ASYNC_DIV2;
  hadc1.Init.Resolution = ADC_RESOLUTION_12B;
  hadc1.Init.DataAlign = ADC_DATAALIGN_RIGHT;
  hadc1.Init.ScanConvMode = ADC_SCAN_ENABLE;
  hadc1.Init.EOCSelection = ADC_EOC_SEQ_CONV;
  hadc1.Init.LowPowerAutoWait = DISABLE;
  hadc1.Init.ContinuousConvMode = DISABLE;
  hadc1.Init.NbrOfConversion = 8;
  hadc1.Init.DiscontinuousConvMode = DISABLE;
  hadc1.Init.NbrOfDiscConversion = 1;
  hadc1.Init.ExternalTrigConv = ADC_EXTERNALTRIG_T6_TRGO;
  hadc1.Init.ExternalTrigConvEdge = ADC_EXTERNALTRIGCONVEDGE_RISING;
  hadc1.Init.DMAContinuousRequests = ENABLE;
  hadc1.Init.Overrun = ADC_OVR_DATA_PRESERVED;
  hadc1.Init.OversamplingMode = ENABLE;
  hadc1.Init.Oversampling.Ratio = ADC_OVERSAMPLING_RATIO_16;
  hadc1.Init.Oversampling.RightBitShift = ADC_RIGHTBITSHIFT_NONE;
  hadc1.Init.Oversampling.TriggeredMode = ADC_TRIGGEREDMODE_SINGLE_TRIGGER;
  hadc1.Init.Oversampling.OversamplingStopReset = ADC_REGOVERSAMPLING_CONTINUED_MODE;
  if (HAL_ADC_Init(&hadc1) != HAL_OK)
  {
    Error_Handler();
  }
  /** Configure the ADC multi-mode
  */
  multimode.Mode = ADC_MODE_INDEPENDENT;
  if (HAL_ADCEx_MultiModeConfigChannel(&hadc1, &multimode) != HAL_OK)
  {
    Error_Handler();
  }
  /** Configure Regular Channel
  */
  sConfig.Channel = ADC_CHANNEL_1;
  sConfig.Rank = ADC_REGULAR_RANK_1;
  sConfig.SamplingTime = ADC_SAMPLETIME_24CYCLES_5;
  sConfig.SingleDiff = ADC_SINGLE_ENDED;
  sConfig.OffsetNumber = ADC_OFFSET_NONE;
  sConfig.Offset = 0;
  if (HAL_ADC_ConfigChannel(&hadc1, &sConfig) != HAL_OK)
  {
    Error_Handler();
  }
  /** Configure Regular Channel
  */
  sConfig.Channel = ADC_CHANNEL_2;
  sConfig.Rank = ADC_REGULAR_RANK_2;
  if (HAL_ADC_ConfigChannel(&hadc1, &sConfig) != HAL_OK)
  {
    Error_Handler();
  }
  /** Configure Regular Channel
  */
  sConfig.Channel = ADC_CHANNEL_3;
  sConfig.Rank = ADC_REGULAR_RANK_3;
  if (HAL_ADC_ConfigChannel(&hadc1, &sConfig) != HAL_OK)
  {
    Error_Handler();
  }
  /** Configure Regular Channel
  */
  sConfig.Channel = ADC_CHANNEL_4;
  sConfig.Rank = ADC_REGULAR_RANK_4;
  if (HAL_ADC_ConfigChannel(&hadc1, &sConfig) != HAL_OK)
  {
    Error_Handler();
  }
  /** Configure Regular Channel
  */
  sConfig.Channel = ADC_CHANNEL_5;
  sConfig.Rank = ADC_REGULAR_RANK_5;
  if (HAL_ADC_ConfigChannel(&hadc1, &sConfig) != HAL_OK)
  {
    Error_Handler();
  }
  /** Configure Regular Channel
  */
  sConfig.Channel = ADC_CHANNEL_6;
  sConfig.Rank = ADC_REGULAR_RANK_6;
  if (HAL_ADC_ConfigChannel(&hadc1, &sConfig) != HAL_OK)
  {
    Error_Handler();
  }
  /** Configure Regular Channel
  */
  sConfig.Channel = ADC_CHANNEL_13;
  sConfig.Rank = ADC_REGULAR_RANK_7;
  if (HAL_ADC_ConfigChannel(&hadc1, &sConfig) != HAL_OK)
  {
    Error_Handler();
  }
  /** Configure Regular Channel
  */
  sConfig.Channel = ADC_CHANNEL_14;
  sConfig.Rank = ADC_REGULAR_RANK_8;
  if (HAL_ADC_ConfigChannel(&hadc1, &sConfig) != HAL_OK)
  {
    Error_Handler();
  }

}

static void MX_DAC1_Init(void)
{

  DAC_ChannelConfTypeDef sConfig = {0};

  /** DAC Initialization
  */
  hdac1.Instance = DAC1;
  if (HAL_DAC_Init(&hdac1) != HAL_OK)
  {
    Error_Handler();
  }
  /** DAC channel OUT1 config
  */
  sConfig.DAC_SampleAndHold = DAC_SAMPLEANDHOLD_DISABLE;
  sConfig.DAC_Trigger = DAC_TRIGGER_NONE;
  sConfig.DAC_OutputBuffer = DAC_OUTPUTBUFFER_ENABLE;
  sConfig.DAC_ConnectOnChipPeripheral = DAC_CHIPCONNECT_DISABLE;
  sConfig.DAC_UserTrimming = DAC_TRIMMING_FACTORY;
  if (HAL_DAC_ConfigChannel(&hdac1, &sConfig, DAC_CHANNEL_1) != HAL_OK)
  {
    Error_Handler();
  }
  /** DAC channel OUT2 config
  */
  sConfig.DAC_ConnectOnChipPeripheral = DAC_CHIPCONNECT_DISABLE;
  if (HAL_DAC_ConfigChannel(&hdac1, &sConfig, DAC_CHANNEL_2) != HAL_OK)
  {
    Error_Handler();
  }

}

static void MX_I2C2_Init(void)
{

  hi2c2.Instance = I2C2;
  hi2c2.Init.Timing = 0x00501D63;
  hi2c2.Init.OwnAddress1 = 0;
  hi2c2.Init.AddressingMode = I2C_ADDRESSINGMODE_7BIT;
  hi2c2.Init.DualAddressMode = I2C_DUALADDRESS_DISABLE;
  hi2c2.Init.OwnAddress2 = 0;
  hi2c2.Init.OwnAddress2Masks = I2C_OA2_NOMASK;
  hi2c2.Init.GeneralCallMode = I2C_GENERALCALL_DISABLE;
  hi2c2.Init.NoStretchMode = I2C_NOSTRETCH_DISABLE;
  if (HAL_I2C_Init(&hi2c2) != HAL_OK)
  {
    Error_Handler();
  }
  /** Configure Analogue filter
  */
  if (HAL_I2CEx_ConfigAnalogFilter(&hi2c2, I2C_ANALOGFILTER_ENABLE) != HAL_OK)
  {
    Error_Handler();
  }
  /** Configure Digital filter
  */
  if (HAL_I2CEx_ConfigDigitalFilter(&hi2c2, 0) != HAL_OK)
  {
    Error_Handler();
  }

}

static void MX_SAI1_Init(void)
{

  hsai_BlockA1.Instance = SAI1_Block_A;
  hsai_BlockA1.Init.AudioMode = SAI_MODEMASTER_TX;
  hsai_BlockA1.Init.Synchro = SAI_ASYNCHRONOUS;
  hsai_BlockA1.Init.OutputDrive = SAI_OUTPUTDRIVE_ENABLE;
  hsai_BlockA1.Init.NoDivider = SAI_MASTERDIVIDER_ENABLE;
  hsai_BlockA1.Init.FIFOThreshold = SAI_FIFOTHRESHOLD_HF;
  hsai_BlockA1.Init.AudioFrequency = SAI_AUDIO_FREQUENCY_32K;
  hsai_BlockA1.Init.SynchroExt = SAI_SYNCEXT_DISABLE;
  hsai_BlockA1.Init.MonoStereoMode = SAI_STEREOMODE;
  hsai_BlockA1.Init.CompandingMode = SAI_NOCOMPANDING;
  hsai_BlockA1.Init.TriState = SAI_OUTPUT_NOTRELEASED;
  if (HAL_SAI_InitProtocol(&hsai_BlockA1, SAI_I2S_STANDARD, SAI_PROTOCOL_DATASIZE_16BIT, 2) != HAL_OK)
  {
    Error_Handler();
  }
  hsai_BlockB1.Instance = SAI1_Block_B;
  hsai_BlockB1.Init.AudioMode = SAI_MODESLAVE_RX;
  hsai_BlockB1.Init.Synchro = SAI_SYNCHRONOUS;
  hsai_BlockB1.Init.OutputDrive = SAI_OUTPUTDRIVE_DISABLE;
  hsai_BlockB1.Init.FIFOThreshold = SAI_FIFOTHRESHOLD_EMPTY;
  hsai_BlockB1.Init.SynchroExt = SAI_SYNCEXT_DISABLE;
  hsai_BlockB1.Init.MonoStereoMode = SAI_STEREOMODE;
  hsai_BlockB1.Init.CompandingMode = SAI_NOCOMPANDING;
  hsai_BlockB1.Init.TriState = SAI_OUTPUT_NOTRELEASED;
  if (HAL_SAI_InitProtocol(&hsai_BlockB1, SAI_I2S_STANDARD, SAI_PROTOCOL_DATASIZE_16BIT, 2) != HAL_OK)
  {
    Error_Handler();
  }

}

static void MX_SPI2_Init(void)
{

  /* SPI2 parameter configuration*/
  hspi2.Instance = SPI2;
  hspi2.Init.Mode = SPI_MODE_MASTER;
  hspi2.Init.Direction = SPI_DIRECTION_2LINES;
  hspi2.Init.DataSize = SPI_DATASIZE_8BIT;
  hspi2.Init.CLKPolarity = SPI_POLARITY_HIGH;
  hspi2.Init.CLKPhase = SPI_PHASE_2EDGE;
  hspi2.Init.NSS = SPI_NSS_SOFT;
  hspi2.Init.BaudRatePrescaler = SPI_BAUDRATEPRESCALER_2;
  hspi2.Init.FirstBit = SPI_FIRSTBIT_MSB;
  hspi2.Init.TIMode = SPI_TIMODE_DISABLE;
  hspi2.Init.CRCCalculation = SPI_CRCCALCULATION_DISABLE;
  hspi2.Init.CRCPolynomial = 7;
  hspi2.Init.CRCLength = SPI_CRC_LENGTH_DATASIZE;
  hspi2.Init.NSSPMode = SPI_NSS_PULSE_DISABLE;
  if (HAL_SPI_Init(&hspi2) != HAL_OK)
  {
    Error_Handler();
  }

}

static void MX_TIM1_Init(void)
{

  TIM_ClockConfigTypeDef sClockSourceConfig = {0};
  TIM_MasterConfigTypeDef sMasterConfig = {0};
  TIM_OC_InitTypeDef sConfigOC = {0};
  TIM_BreakDeadTimeConfigTypeDef sBreakDeadTimeConfig = {0};

  htim1.Instance = TIM1;
  htim1.Init.Prescaler = 0;
  htim1.Init.CounterMode = TIM_COUNTERMODE_UP;
  htim1.Init.Period = 256;
  htim1.Init.ClockDivision = TIM_CLOCKDIVISION_DIV1;
  htim1.Init.RepetitionCounter = 0;
  htim1.Init.AutoReloadPreload = TIM_AUTORELOAD_PRELOAD_DISABLE;
  if (HAL_TIM_Base_Init(&htim1) != HAL_OK)
  {
    Error_Handler();
  }
  sClockSourceConfig.ClockSource = TIM_CLOCKSOURCE_INTERNAL;
  if (HAL_TIM_ConfigClockSource(&htim1, &sClockSourceConfig) != HAL_OK)
  {
    Error_Handler();
  }
  if (HAL_TIM_PWM_Init(&htim1) != HAL_OK)
  {
    Error_Handler();
  }
  sMasterConfig.MasterOutputTrigger = TIM_TRGO_RESET;
  sMasterConfig.MasterOutputTrigger2 = TIM_TRGO2_RESET;
  sMasterConfig.MasterSlaveMode = TIM_MASTERSLAVEMODE_DISABLE;
  if (HAL_TIMEx_MasterConfigSynchronization(&htim1, &sMasterConfig) != HAL_OK)
  {
    Error_Handler();
  }
  sConfigOC.OCMode = TIM_OCMODE_PWM1;
  sConfigOC.Pulse = 0;
  sConfigOC.OCPolarity = TIM_OCPOLARITY_HIGH;
  sConfigOC.OCNPolarity = TIM_OCNPOLARITY_HIGH;
  sConfigOC.OCFastMode = TIM_OCFAST_ENABLE;
  sConfigOC.OCIdleState = TIM_OCIDLESTATE_RESET;
  sConfigOC.OCNIdleState = TIM_OCNIDLESTATE_RESET;
  if (HAL_TIM_PWM_ConfigChannel(&htim1, &sConfigOC, TIM_CHANNEL_1) != HAL_OK)
  {
    Error_Handler();
  }
  if (HAL_TIM_PWM_ConfigChannel(&htim1, &sConfigOC, TIM_CHANNEL_2) != HAL_OK)
  {
    Error_Handler();
  }
  if (HAL_TIM_PWM_ConfigChannel(&htim1, &sConfigOC, TIM_CHANNEL_3) != HAL_OK)
  {
    Error_Handler();
  }
  if (HAL_TIM_PWM_ConfigChannel(&htim1, &sConfigOC, TIM_CHANNEL_4) != HAL_OK)
  {
    Error_Handler();
  }
  sBreakDeadTimeConfig.OffStateRunMode = TIM_OSSR_DISABLE;
  sBreakDeadTimeConfig.OffStateIDLEMode = TIM_OSSI_DISABLE;
  sBreakDeadTimeConfig.LockLevel = TIM_LOCKLEVEL_OFF;
  sBreakDeadTimeConfig.DeadTime = 0;
  sBreakDeadTimeConfig.BreakState = TIM_BREAK_DISABLE;
  sBreakDeadTimeConfig.BreakPolarity = TIM_BREAKPOLARITY_HIGH;
  sBreakDeadTimeConfig.BreakFilter = 0;
  sBreakDeadTimeConfig.Break2State = TIM_BREAK2_DISABLE;
  sBreakDeadTimeConfig.Break2Polarity = TIM_BREAK2POLARITY_HIGH;
  sBreakDeadTimeConfig.Break2Filter = 0;
  sBreakDeadTimeConfig.AutomaticOutput = TIM_AUTOMATICOUTPUT_DISABLE;
  if (HAL_TIMEx_ConfigBreakDeadTime(&htim1, &sBreakDeadTimeConfig) != HAL_OK)
  {
    Error_Handler();
  }
  HAL_TIM_MspPostInit(&htim1);

}

static void MX_TIM2_Init(void)
{

  TIM_ClockConfigTypeDef sClockSourceConfig = {0};
  TIM_MasterConfigTypeDef sMasterConfig = {0};
  TIM_OC_InitTypeDef sConfigOC = {0};

  htim2.Instance = TIM2;
  htim2.Init.Prescaler = 0;
  htim2.Init.CounterMode = TIM_COUNTERMODE_UP;
  htim2.Init.Period = 256;
  htim2.Init.ClockDivision = TIM_CLOCKDIVISION_DIV1;
  htim2.Init.AutoReloadPreload = TIM_AUTORELOAD_PRELOAD_DISABLE;
  if (HAL_TIM_Base_Init(&htim2) != HAL_OK)
  {
    Error_Handler();
  }
  sClockSourceConfig.ClockSource = TIM_CLOCKSOURCE_INTERNAL;
  if (HAL_TIM_ConfigClockSource(&htim2, &sClockSourceConfig) != HAL_OK)
  {
    Error_Handler();
  }
  if (HAL_TIM_PWM_Init(&htim2) != HAL_OK)
  {
    Error_Handler();
  }
  sMasterConfig.MasterOutputTrigger = TIM_TRGO_RESET;
  sMasterConfig.MasterSlaveMode = TIM_MASTERSLAVEMODE_DISABLE;
  if (HAL_TIMEx_MasterConfigSynchronization(&htim2, &sMasterConfig) != HAL_OK)
  {
    Error_Handler();
  }
  sConfigOC.OCMode = TIM_OCMODE_PWM1;
  sConfigOC.Pulse = 0;
  sConfigOC.OCPolarity = TIM_OCPOLARITY_HIGH;
  sConfigOC.OCFastMode = TIM_OCFAST_DISABLE;
  if (HAL_TIM_PWM_ConfigChannel(&htim2, &sConfigOC, TIM_CHANNEL_2) != HAL_OK)
  {
    Error_Handler();
  }
  sConfigOC.OCFastMode = TIM_OCFAST_ENABLE;
  if (HAL_TIM_PWM_ConfigChannel(&htim2, &sConfigOC, TIM_CHANNEL_3) != HAL_OK)
  {
    Error_Handler();
  }
  if (HAL_TIM_PWM_ConfigChannel(&htim2, &sConfigOC, TIM_CHANNEL_4) != HAL_OK)
  {
    Error_Handler();
  }
  HAL_TIM_MspPostInit(&htim2);

}

static void MX_TIM3_Init(void)
{

  TIM_ClockConfigTypeDef sClockSourceConfig = {0};
  TIM_MasterConfigTypeDef sMasterConfig = {0};
  TIM_OC_InitTypeDef sConfigOC = {0};

  htim3.Instance = TIM3;
  htim3.Init.Prescaler = 0;
  htim3.Init.CounterMode = TIM_COUNTERMODE_UP;
  htim3.Init.Period = 256;
  htim3.Init.ClockDivision = TIM_CLOCKDIVISION_DIV1;
  htim3.Init.AutoReloadPreload = TIM_AUTORELOAD_PRELOAD_DISABLE;
  if (HAL_TIM_Base_Init(&htim3) != HAL_OK)
  {
    Error_Handler();
  }
  sClockSourceConfig.ClockSource = TIM_CLOCKSOURCE_INTERNAL;
  if (HAL_TIM_ConfigClockSource(&htim3, &sClockSourceConfig) != HAL_OK)
  {
    Error_Handler();
  }
  if (HAL_TIM_PWM_Init(&htim3) != HAL_OK)
  {
    Error_Handler();
  }
  sMasterConfig.MasterOutputTrigger = TIM_TRGO_RESET;
  sMasterConfig.MasterSlaveMode = TIM_MASTERSLAVEMODE_DISABLE;
  if (HAL_TIMEx_MasterConfigSynchronization(&htim3, &sMasterConfig) != HAL_OK)
  {
    Error_Handler();
  }
  sConfigOC.OCMode = TIM_OCMODE_PWM1;
  sConfigOC.Pulse = 0;
  sConfigOC.OCPolarity = TIM_OCPOLARITY_HIGH;
  sConfigOC.OCFastMode = TIM_OCFAST_DISABLE;
  if (HAL_TIM_PWM_ConfigChannel(&htim3, &sConfigOC, TIM_CHANNEL_1) != HAL_OK)
  {
    Error_Handler();
  }
  if (HAL_TIM_PWM_ConfigChannel(&htim3, &sConfigOC, TIM_CHANNEL_2) != HAL_OK)
  {
    Error_Handler();
  }
  if (HAL_TIM_PWM_ConfigChannel(&htim3, &sConfigOC, TIM_CHANNEL_3) != HAL_OK)
  {
    Error_Handler();
  }
  if (HAL_TIM_PWM_ConfigChannel(&htim3, &sConfigOC, TIM_CHANNEL_4) != HAL_OK)
  {
    Error_Handler();
  }
  HAL_TIM_MspPostInit(&htim3);

}

static void MX_TIM4_Init(void)
{

  TIM_ClockConfigTypeDef sClockSourceConfig = {0};
  TIM_MasterConfigTypeDef sMasterConfig = {0};
  TIM_OC_InitTypeDef sConfigOC = {0};

  htim4.Instance = TIM4;
  htim4.Init.Prescaler = 0;
  htim4.Init.CounterMode = TIM_COUNTERMODE_UP;
  htim4.Init.Period = 256;
  htim4.Init.ClockDivision = TIM_CLOCKDIVISION_DIV1;
  htim4.Init.AutoReloadPreload = TIM_AUTORELOAD_PRELOAD_DISABLE;
  if (HAL_TIM_Base_Init(&htim4) != HAL_OK)
  {
    Error_Handler();
  }
  sClockSourceConfig.ClockSource = TIM_CLOCKSOURCE_INTERNAL;
  if (HAL_TIM_ConfigClockSource(&htim4, &sClockSourceConfig) != HAL_OK)
  {
    Error_Handler();
  }
  if (HAL_TIM_PWM_Init(&htim4) != HAL_OK)
  {
    Error_Handler();
  }
  sMasterConfig.MasterOutputTrigger = TIM_TRGO_RESET;
  sMasterConfig.MasterSlaveMode = TIM_MASTERSLAVEMODE_DISABLE;
  if (HAL_TIMEx_MasterConfigSynchronization(&htim4, &sMasterConfig) != HAL_OK)
  {
    Error_Handler();
  }
  sConfigOC.OCMode = TIM_OCMODE_PWM1;
  sConfigOC.Pulse = 0;
  sConfigOC.OCPolarity = TIM_OCPOLARITY_HIGH;
  sConfigOC.OCFastMode = TIM_OCFAST_ENABLE;
  if (HAL_TIM_PWM_ConfigChannel(&htim4, &sConfigOC, TIM_CHANNEL_2) != HAL_OK)
  {
    Error_Handler();
  }
  if (HAL_TIM_PWM_ConfigChannel(&htim4, &sConfigOC, TIM_CHANNEL_3) != HAL_OK)
  {
    Error_Handler();
  }
  HAL_TIM_MspPostInit(&htim4);

}

static void MX_TIM5_Init(void)
{

  TIM_ClockConfigTypeDef sClockSourceConfig = {0};
  TIM_MasterConfigTypeDef sMasterConfig = {0};

  htim5.Instance = TIM5;
  htim5.Init.Prescaler = 80;
  htim5.Init.CounterMode = TIM_COUNTERMODE_UP;
  htim5.Init.Period = 4294967295;
  htim5.Init.ClockDivision = TIM_CLOCKDIVISION_DIV1;
  htim5.Init.AutoReloadPreload = TIM_AUTORELOAD_PRELOAD_DISABLE;
  if (HAL_TIM_Base_Init(&htim5) != HAL_OK)
  {
    Error_Handler();
  }
  sClockSourceConfig.ClockSource = TIM_CLOCKSOURCE_INTERNAL;
  if (HAL_TIM_ConfigClockSource(&htim5, &sClockSourceConfig) != HAL_OK)
  {
    Error_Handler();
  }
  sMasterConfig.MasterOutputTrigger = TIM_TRGO_RESET;
  sMasterConfig.MasterSlaveMode = TIM_MASTERSLAVEMODE_DISABLE;
  if (HAL_TIMEx_MasterConfigSynchronization(&htim5, &sMasterConfig) != HAL_OK)
  {
    Error_Handler();
  }

}

static void MX_TIM6_Init(void)
{

  TIM_MasterConfigTypeDef sMasterConfig = {0};

  htim6.Instance = TIM6;
  htim6.Init.Prescaler = 0;
  htim6.Init.CounterMode = TIM_COUNTERMODE_UP;
  htim6.Init.Period = 12000;
  htim6.Init.AutoReloadPreload = TIM_AUTORELOAD_PRELOAD_DISABLE;
  if (HAL_TIM_Base_Init(&htim6) != HAL_OK)
  {
    Error_Handler();
  }
  sMasterConfig.MasterOutputTrigger = TIM_TRGO_UPDATE;
  sMasterConfig.MasterSlaveMode = TIM_MASTERSLAVEMODE_DISABLE;
  if (HAL_TIMEx_MasterConfigSynchronization(&htim6, &sMasterConfig) != HAL_OK)
  {
    Error_Handler();
  }

}

static void MX_TSC_Init(void)
{

  /** Configure the TSC peripheral
  */
  htsc.Instance = TSC;
  htsc.Init.CTPulseHighLength = TSC_CTPH_7CYCLES;
  htsc.Init.CTPulseLowLength = TSC_CTPL_7CYCLES;
  htsc.Init.SpreadSpectrum = DISABLE;
  htsc.Init.SpreadSpectrumDeviation = 32;
  htsc.Init.SpreadSpectrumPrescaler = TSC_SS_PRESC_DIV1;
  htsc.Init.PulseGeneratorPrescaler = TSC_PG_PRESC_DIV2;
  htsc.Init.MaxCountValue = TSC_MCV_16383;
  htsc.Init.IODefaultMode = TSC_IODEF_OUT_PP_LOW;
  htsc.Init.SynchroPinPolarity = TSC_SYNC_POLARITY_FALLING;
  htsc.Init.AcquisitionMode = TSC_ACQ_MODE_NORMAL;
  htsc.Init.MaxCountInterrupt = DISABLE;
  htsc.Init.ChannelIOs = TSC_GROUP1_IO2|TSC_GROUP1_IO3|TSC_GROUP1_IO4|TSC_GROUP2_IO2
                    |TSC_GROUP2_IO3|TSC_GROUP2_IO4|TSC_GROUP3_IO3|TSC_GROUP3_IO4
                    |TSC_GROUP4_IO2|TSC_GROUP4_IO3|TSC_GROUP4_IO4|TSC_GROUP5_IO2
                    |TSC_GROUP5_IO3|TSC_GROUP5_IO4|TSC_GROUP6_IO2|TSC_GROUP6_IO3
                    |TSC_GROUP7_IO2|TSC_GROUP7_IO3;
  htsc.Init.ShieldIOs = 0;
  htsc.Init.SamplingIOs = TSC_GROUP1_IO1|TSC_GROUP2_IO1|TSC_GROUP3_IO2|TSC_GROUP4_IO1
                    |TSC_GROUP5_IO1|TSC_GROUP6_IO1|TSC_GROUP7_IO1;
  if (HAL_TSC_Init(&htsc) != HAL_OK)
  {
    Error_Handler();
  }

}

static void MX_USART3_UART_Init(void)
{

  huart3.Instance = USART3;
  #ifdef DEBUG
  huart3.Init.BaudRate = 115200;
  #else
  huart3.Init.BaudRate = 31250;
  #endif

  huart3.Init.WordLength = UART_WORDLENGTH_8B;
  huart3.Init.StopBits = UART_STOPBITS_1;
  huart3.Init.Parity = UART_PARITY_NONE;
  huart3.Init.Mode = UART_MODE_TX_RX;
  huart3.Init.HwFlowCtl = UART_HWCONTROL_NONE;
  huart3.Init.OverSampling = UART_OVERSAMPLING_16;
  huart3.Init.OneBitSampling = UART_ONE_BIT_SAMPLE_DISABLE;
  huart3.AdvancedInit.AdvFeatureInit = UART_ADVFEATURE_RXOVERRUNDISABLE_INIT;
  huart3.AdvancedInit.OverrunDisable = UART_ADVFEATURE_OVERRUN_DISABLE;
  if (HAL_UART_Init(&huart3) != HAL_OK)
  {
    Error_Handler();
  }

}

static void MX_USB_OTG_FS_PCD_Init(void)
{

  hpcd_USB_OTG_FS.Instance = USB_OTG_FS;
  hpcd_USB_OTG_FS.Init.dev_endpoints = 6;
  hpcd_USB_OTG_FS.Init.speed = PCD_SPEED_FULL;
  hpcd_USB_OTG_FS.Init.phy_itface = PCD_PHY_EMBEDDED;
  hpcd_USB_OTG_FS.Init.Sof_enable = DISABLE;
  hpcd_USB_OTG_FS.Init.low_power_enable = DISABLE;
  hpcd_USB_OTG_FS.Init.lpm_enable = DISABLE;
  hpcd_USB_OTG_FS.Init.battery_charging_enable = DISABLE;
  hpcd_USB_OTG_FS.Init.use_dedicated_ep1 = DISABLE;
  hpcd_USB_OTG_FS.Init.vbus_sensing_enable = DISABLE;
  if (HAL_PCD_Init(&hpcd_USB_OTG_FS) != HAL_OK)
  {
    Error_Handler();
  }

}

static void MX_DMA_Init(void)
{

  /* DMA controller clock enable */
  __HAL_RCC_DMA2_CLK_ENABLE();
  __HAL_RCC_DMA1_CLK_ENABLE();

  /* DMA interrupt init */
  /* DMA1_Channel1_IRQn interrupt configuration */
  HAL_NVIC_SetPriority(DMA1_Channel1_IRQn, 0, 0);
  HAL_NVIC_EnableIRQ(DMA1_Channel1_IRQn);
  /* DMA1_Channel2_IRQn interrupt configuration */
  HAL_NVIC_SetPriority(DMA1_Channel2_IRQn, 0, 0);
  HAL_NVIC_EnableIRQ(DMA1_Channel2_IRQn);
  /* DMA1_Channel3_IRQn interrupt configuration */
  HAL_NVIC_SetPriority(DMA1_Channel3_IRQn, 0, 0);
  HAL_NVIC_EnableIRQ(DMA1_Channel3_IRQn);
  /* DMA1_Channel4_IRQn interrupt configuration */
  HAL_NVIC_SetPriority(DMA1_Channel4_IRQn, 0, 0);
  HAL_NVIC_EnableIRQ(DMA1_Channel4_IRQn);
  /* DMA1_Channel5_IRQn interrupt configuration */
  HAL_NVIC_SetPriority(DMA1_Channel5_IRQn, 0, 0);
  HAL_NVIC_EnableIRQ(DMA1_Channel5_IRQn);
  /* DMA2_Channel1_IRQn interrupt configuration */
  HAL_NVIC_SetPriority(DMA2_Channel1_IRQn, 1, 0);
  HAL_NVIC_EnableIRQ(DMA2_Channel1_IRQn);
  /* DMA2_Channel2_IRQn interrupt configuration */
  HAL_NVIC_SetPriority(DMA2_Channel2_IRQn, 1, 0);
  HAL_NVIC_EnableIRQ(DMA2_Channel2_IRQn);

}

static void MX_GPIO_Init(void)
{
  GPIO_InitTypeDef GPIO_InitStruct = {0};

  /* GPIO Ports Clock Enable */
  __HAL_RCC_GPIOE_CLK_ENABLE();
  __HAL_RCC_GPIOC_CLK_ENABLE();
  __HAL_RCC_GPIOH_CLK_ENABLE();
  __HAL_RCC_GPIOA_CLK_ENABLE();
  __HAL_RCC_GPIOB_CLK_ENABLE();
  __HAL_RCC_GPIOD_CLK_ENABLE();

  /*Configure GPIO pin Output Level */
  HAL_GPIO_WritePin(GPIOD, N5_Pin|N4_Pin|N1_Pin|N2_Pin
                          |N3_Pin, GPIO_PIN_RESET);

  /*Configure GPIO pin Output Level */
  HAL_GPIO_WritePin(GPIOE, CS2_Pin|CS1_Pin, GPIO_PIN_SET);

  /*Configure GPIO pins : IO1_Pin IO2_Pin IO3_Pin */
  GPIO_InitStruct.Pin = IO1_Pin|IO2_Pin|IO3_Pin;
  GPIO_InitStruct.Mode = GPIO_MODE_INPUT;
  GPIO_InitStruct.Pull = GPIO_PULLUP;
  HAL_GPIO_Init(GPIOC, &GPIO_InitStruct);

  /*Configure GPIO pin : CLKIN_Pin */
  GPIO_InitStruct.Pin = CLKIN_Pin;
  GPIO_InitStruct.Mode = GPIO_MODE_IT_FALLING;
  GPIO_InitStruct.Pull = GPIO_PULLUP;
  HAL_GPIO_Init(CLKIN_GPIO_Port, &GPIO_InitStruct);

  /*Configure GPIO pins : SENSE1_Pin SENSE2_Pin */
  GPIO_InitStruct.Pin = SENSE1_Pin|SENSE2_Pin;
  GPIO_InitStruct.Mode = GPIO_MODE_INPUT;
  GPIO_InitStruct.Pull = GPIO_PULLUP;
  HAL_GPIO_Init(GPIOE, &GPIO_InitStruct);

  /*Configure GPIO pins : N5_Pin N4_Pin N1_Pin N2_Pin
                           N3_Pin */
  GPIO_InitStruct.Pin = N5_Pin|N4_Pin|N1_Pin|N2_Pin
                          |N3_Pin;
  GPIO_InitStruct.Mode = GPIO_MODE_OUTPUT_PP;
  GPIO_InitStruct.Pull = GPIO_NOPULL;
  GPIO_InitStruct.Speed = GPIO_SPEED_FREQ_LOW;
  HAL_GPIO_Init(GPIOD, &GPIO_InitStruct);

  /*Configure GPIO pin : DEBUG_Pin */
  GPIO_InitStruct.Pin = DEBUG_Pin;
  GPIO_InitStruct.Mode = GPIO_MODE_INPUT;
  GPIO_InitStruct.Pull = GPIO_PULLUP;
  HAL_GPIO_Init(DEBUG_GPIO_Port, &GPIO_InitStruct);

  /*Configure GPIO pins : CS2_Pin CS1_Pin */
  GPIO_InitStruct.Pin = CS2_Pin|CS1_Pin;
  GPIO_InitStruct.Mode = GPIO_MODE_OUTPUT_PP;
  GPIO_InitStruct.Pull = GPIO_NOPULL;
  GPIO_InitStruct.Speed = GPIO_SPEED_FREQ_VERY_HIGH;
  HAL_GPIO_Init(GPIOE, &GPIO_InitStruct);

  /* EXTI interrupt init*/
  HAL_NVIC_SetPriority(EXTI2_IRQn, 0, 0);
  HAL_NVIC_EnableIRQ(EXTI2_IRQn);

}

void Error_Handler(void)
{
}

/************************ (C) COPYRIGHT STMicroelectronics *****END OF FILE****/
